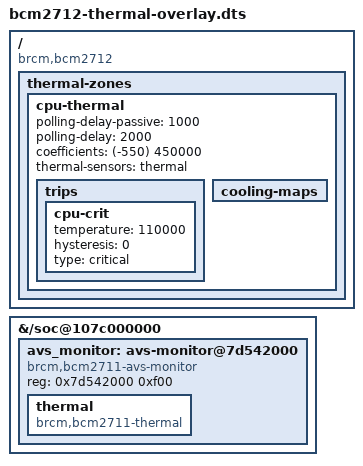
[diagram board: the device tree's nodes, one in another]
/*
 * Restore CPU thermal monitoring on Raspberry Pi 5 / BCM2712.
 *
 * The bcm2712 device tree shipped in the Talos kernel OCI image (used as the
 * base DTB by this project) is the stripped mainline variant and omits the
 * AVS monitor and thermal-zones nodes entirely. The bcm2711_thermal driver is
 * built into the Talos kernel, so it only needs the device-tree nodes to bind.
 *
 * This overlay re-adds the avs-monitor syscon (with its brcm,bcm2711-thermal
 * sensor) and a cpu-thermal zone, matching the values the Raspberry Pi
 * firmware DTB provides. Nodes are added by absolute path because the base DTB
 * has no symbols/labels for them.
 *
 * No cooling-maps are defined: the target boards have no PWM fan, so the zone
 * provides temperature monitoring and an emergency critical trip only.
 */
/dts-v1/;
/plugin/;

/ {
	compatible = "brcm,bcm2712";

	fragment@0 {
		target-path = "/soc@107c000000";
		__overlay__ {
			avs_monitor: avs-monitor@7d542000 {
				compatible = "brcm,bcm2711-avs-monitor",
					     "syscon", "simple-mfd";
				reg = <0x7d542000 0xf00>;
				status = "okay";

				thermal: thermal {
					compatible = "brcm,bcm2711-thermal";
					#thermal-sensor-cells = <0>;
				};
			};
		};
	};

	fragment@1 {
		target-path = "/";
		__overlay__ {
			thermal-zones {
				cpu-thermal {
					polling-delay-passive = <1000>;
					polling-delay = <2000>;
					/* BCM2712 calibration: temp(mC) = -550 * raw + 450000 */
					coefficients = <(-550) 450000>;
					thermal-sensors = <&thermal>;

					trips {
						cpu-crit {
							temperature = <110000>;
							hysteresis = <0>;
							type = "critical";
						};
					};

					cooling-maps {
					};
				};
			};
		};
	};
};
